# STM32W108 register map
File version: 1.0
CPU: 
Registers are 32-bit, read-write, reset 0x0 unless marked. A register's access mark holds for its fields unless they carry their own. Offsets are from the block's base; [hi:lo] are bit positions.

## MEM — Memory Control registers
Base 0x40005000
0x00 RAMPROTR1 — Memory protection register1
  [31:0] RAMPROT1
0x04 RAMPROTR2 — Memory protection register2
  [31:0] RAMPROT2
0x08 RAMPROTR3 — Memory protection register3
  [31:0] RAMPROT3 — RAMPROT1
0x0C RAMPROTR4 — Memory protection register4
  [31:0] RAMPROT4
0x10 RAMPROTR5 — Memory protection register5
  [31:0] RAMPROT5
0x14 RAMPROTR6 — Memory protection register6
  [31:0] RAMPROT6
0x18 RAMPROTR7 — Memory protection register7
  [31:0] RAMPROT7
0x1C RAMPROTR8 — Memory protection register8
  [31:0] RAMPROT8
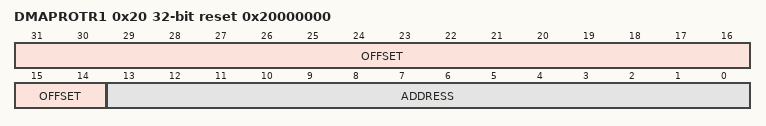
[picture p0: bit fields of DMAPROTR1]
0x20 DMAPROTR1 ro reset 0x20000000 — DMA protection register1
  [31:14] OFFSET — offset in RAM
  [13:0] ADDRESS — DMA protection fault, faulting address
0x24 DMAPROTR2 ro — DMA protection register2
  [2:0] CHANNEL — DMA protection fault, faulting channel
0x28 RAMCR — Memory configuration register
  [2] WEN — Makes all RAM write access

## SC1_DMA — Serial controller 1 (Direct memory access)
Base 0x4000C800
0x00 SC1_DMARXBEGADDAR reset 0x20000000 — Serial controller receive DMA begin address channel A register
  [12:0] ADD
0x04 SC1_DMARXENDADDAR — Serial controller receive DMA end address channel A register
  [12:0] ADD
0x08 SC1_DMARXBEGADDBR reset 0x20000000 — Serial controller receive DMA begin address channel B register
  [12:0] ADD
0x0C SC1_DMARXENDADDBR reset 0x20000000 — Serial controller receive DMA end address channel B register
  [12:0] ADD
0x10 SC1_DMATXBEGADDAR reset 0x20000000 — Serial controller transmit DMA begin address channel A register
  [12:0] ADD
0x14 SC1_DMATXENDADDAR reset 0x20000000 — Serial controller transmit DMA end address channel A register
  [12:0] ADD
0x18 SC1_DMATXBEGADDBR reset 0x20000000 — Serial controller transmit DMA begin address channel B register
  [12:0] ADD
0x1C SC1_DMATXENDADDBR reset 0x20000000 — Serial controller transmit DMA end address channel B
  [12:0] ADD
0x20 SC1_DMARXCNTAR — Serial controller receive DMA counter channel A register
  [12:0] CNT
0x24 SC1_DMARXCNTBR — Serial controller receive DMA count channel B register
  [12:0] CNT
0x28 SC1_DMATXCNTR ro — Serial controller transmit DMA counter register
  [12:0] CNT
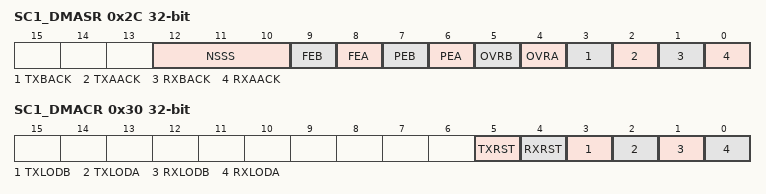
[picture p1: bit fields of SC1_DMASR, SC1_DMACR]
0x2C SC1_DMASR ro — Serial controller DMA status register
  [12:10] NSSS, [9] FEB, [8] FEA, [7] PEB, [6] PEA, [5] OVRB, [4] OVRA, [3] TXBACK, [2] TXAACK, [1] RXBACK, [0] RXAACK
0x30 SC1_DMACR access per field — Serial controller DMA control register
  [5] TXRST wo, [4] RXRST wo, [3] TXLODB rw, [2] TXLODA rw, [1] RXLODB rw, [0] RXLODA rw
0x34 SC1_DMARXERRAR ro — Serial controller receive DMA channel A first error register
  [12:0] ADD
0x38 SC1_DMARXERRBR ro — Serial controller receive DMA channel B first error register
  [12:0] ADD
0x70 SC1_DMARXCNTSAVEDR ro — Serial controller receive DMA saved counter channel B register
  [12:0] CNT

## SC2_DMA — Serial controller 2 (Direct memory access)
Base 0x4000C000
Registers as SC1_DMA (with SC1_DMA read as SC2_DMA); these are added or differ:
0x1C SC2_DMATXENDADDBR reset 0x20000000 — Serial controller transmit DMA end address channel B register
  [12:0] ADD

## SC1_UART — Serial controller 1 (Universal Asynchronous Receiver/Transmitter)
Base 0x4000C848
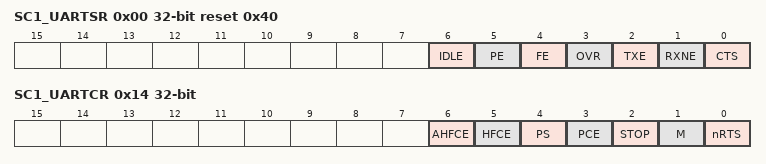
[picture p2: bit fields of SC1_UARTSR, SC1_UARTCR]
0x00 SC1_UARTSR ro reset 0x40 — Serial controller UART status register
  [6] IDLE, [5] PE, [4] FE, [3] OVR, [2] TXE, [1] RXNE, [0] CTS
0x14 SC1_UARTCR — Serial controller UART control register
  [6] AHFCE, [5] HFCE, [4] PS, [3] PCE, [2] STOP, [1] M, [0] nRTS
0x20 SC1_UARTBRR1 — Serial controller UART baud rate register 1
  [15:0] N
0x24 SC1_UARTBRR2 — Serial controller UART baud rate register 2
  [0] F

## SC1_I2C — Serial controller 1 (Serial peripheral interface)
Base 0x4000C844
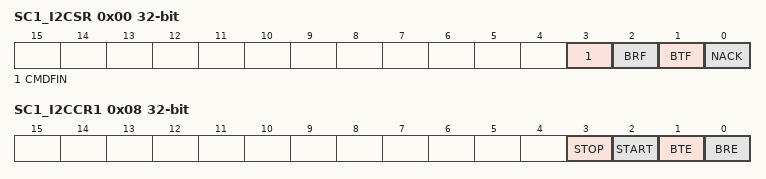
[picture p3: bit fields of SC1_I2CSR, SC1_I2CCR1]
0x00 SC1_I2CSR ro — Serial controller I2C status register
  [3] CMDFIN, [2] BRF, [1] BTF, [0] NACK
0x08 SC1_I2CCR1 — Serial controller I2C control register 1
  [3] STOP, [2] START, [1] BTE, [0] BRE
0x0C SC1_I2CCR2 — Serial controller I2C control register 2
  [0] ACK

## SC2_I2C — Serial controller 2 (Serial peripheral interface)
Base 0x4000C044
Registers as SC1_I2C (with SC1_I2C read as SC2_I2C).

## SC1_SPI — Serial controller 1 (Serial peripheral interface)
Base 0x4000C840
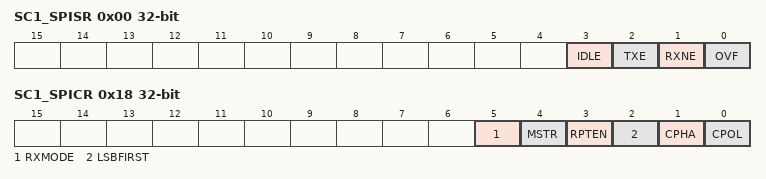
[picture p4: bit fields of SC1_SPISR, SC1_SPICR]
0x00 SC1_SPISR ro — Serial controller SPI status register
  [3] IDLE, [2] TXE, [1] RXNE, [0] OVF
0x18 SC1_SPICR — Serial controller SPI control register
  [5] RXMODE, [4] MSTR, [3] RPTEN, [2] LSBFIRST, [1] CPHA, [0] CPOL

## SC2_SPI — Serial controller 2 (Serial peripheral interface)
Base 0x4000C040
Registers as SC1_SPI (with SC1_SPI read as SC2_SPI).

## MAC_TIM — MAC timer
Base 0x40002038
0x00 MACTMR_CNTR — MACTMR counter register
  [19:0] CNT — MAC timer count
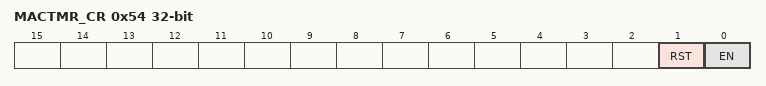
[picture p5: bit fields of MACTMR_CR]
0x54 MACTMR_CR — MACTMR configuration register
  [1] RST — MAC timer reset
  [0] EN — MAC timer enable
